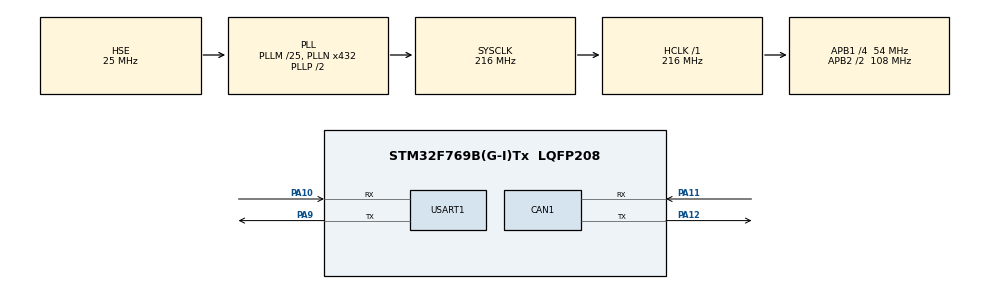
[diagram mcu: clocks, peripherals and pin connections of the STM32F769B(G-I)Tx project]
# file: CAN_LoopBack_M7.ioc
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CAN1.BS1=CAN_BS1_2TQ
CAN1.BS2=CAN_BS2_2TQ
CAN1.CalculateTimeQuantum=296.2962962962963
DSIHOST_CKN.Mode=DSIHost_Standalone
DSIHOST_CKN.Signal=DSIHOST_CKN
DSIHOST_CKP.Mode=DSIHost_Standalone
DSIHOST_CKP.Signal=DSIHOST_CKP
DSIHOST_D0N.Mode=DSIHost_Standalone
DSIHOST_D0N.Signal=DSIHOST_D0N
DSIHOST_D0P.Mode=DSIHost_Standalone
DSIHOST_D0P.Signal=DSIHOST_D0P
DSIHOST_D1N.Mode=DSIHost_Standalone
DSIHOST_D1N.Signal=DSIHOST_D1N
DSIHOST_D1P.Mode=DSIHost_Standalone
DSIHOST_D1P.Signal=DSIHOST_D1P
Mcu.Family=STM32F7
Mcu.Name=STM32F769B(G-I)Tx
Mcu.Package=LQFP208
NVIC.CAN1_RX0_IRQn=true\:0\:0\:false\:false\:true\:true\:true
NVIC.CAN1_RX1_IRQn=true\:0\:0\:false\:false\:true\:true\:true
NVIC.CAN1_SCE_IRQn=true\:0\:0\:false\:false\:true\:true\:true
NVIC.CAN1_TX_IRQn=true\:0\:0\:false\:false\:true\:true\:true
NVIC.PriorityGroup=NVIC_PRIORITYGROUP_4
PA10.Mode=Asynchronous
PA10.Signal=USART1_RX
PA11.Mode=Master
PA11.Signal=CAN1_RX
PA12.Mode=Master
PA12.Signal=CAN1_TX
PA9.Mode=Asynchronous
PA9.Signal=USART1_TX
PH0/OSC_IN.Mode=HSE-External-Oscillator
PH0/OSC_IN.Signal=RCC_OSC_IN
PH1/OSC_OUT.Mode=HSE-External-Oscillator
PH1/OSC_OUT.Signal=RCC_OSC_OUT
ProjectManager.HeapSize=0x200
ProjectManager.StackSize=0x400
ProjectManager.TargetToolchain=SW4STM32
RCC.AHBFreq_Value=216000000
RCC.APB1CLKDivider=RCC_HCLK_DIV4
RCC.APB1Freq_Value=54000000
RCC.APB1TimFreq_Value=108000000
RCC.APB2CLKDivider=RCC_HCLK_DIV2
RCC.APB2Freq_Value=108000000
RCC.APB2TimFreq_Value=216000000
RCC.CortexFreq_Value=216000000
RCC.HCLKFreq_Value=216000000
RCC.HSE_VALUE=25000000
RCC.HSI_VALUE=16000000
RCC.LSE_VALUE=32768
RCC.PLLM=25
RCC.PLLN=432
RCC.PLLSourceVirtual=RCC_PLLSOURCE_HSE
RCC.SYSCLKFreq_VALUE=216000000
RCC.SYSCLKSource=RCC_SYSCLKSOURCE_PLLCLK
RCC.USBFreq_Value=216000000
RCC.VCOOutputFreq_Value=432000000
USART1.VirtualMode-Asynchronous=VM_ASYNC
board=custom

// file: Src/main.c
/* USER CODE BEGIN Header */
/**
  ******************************************************************************
  * @file           : main.c
  * @brief          : Main program body
  ******************************************************************************
  * @attention
  *
  * <h2><center>&copy; Copyright (c) 2020 STMicroelectronics.
  * All rights reserved.</center></h2>
  *
  * This software component is licensed by ST under BSD 3-Clause license,
  * the "License"; You may not use this file except in compliance with the
  * License. You may obtain a copy of the License at:
  *                        opensource.org/licenses/BSD-3-Clause
  *
  ******************************************************************************
  */
/* USER CODE END Header */

#include "main.h"
#include <string.h>

CAN_HandleTypeDef hcan1;

DSI_HandleTypeDef hdsi;

UART_HandleTypeDef huart1;

void SystemClock_Config(void);
static void MX_GPIO_Init(void);
static void MX_CAN1_Init(void);
static void MX_USART1_UART_Init(void);
static void MX_DSIHOST_DSI_Init(void);
void CAN1Tx(void);
void CAN1Rx(void);
void CANFilterConfig(void);

int main(void)
{

  /* MCU Configuration--------------------------------------------------------*/

  /* Reset of all peripherals, Initializes the Flash interface and the Systick. */
  HAL_Init();

  /* Configure the system clock */
  SystemClock_Config();

  /* Initialize all configured peripherals */
  MX_GPIO_Init();
  MX_CAN1_Init();

  CANFilterConfig();

  // Enable Interrupts before starting CAN
  HAL_CAN_ActivateNotification(&hcan1, CAN_IT_TX_MAILBOX_EMPTY | CAN_IT_RX_FIFO0_MSG_PENDING | CAN_IT_RX_FIFO1_MSG_PENDING | CAN_IT_ERROR);

  HAL_CAN_Start(&hcan1);

  MX_USART1_UART_Init();
  MX_DSIHOST_DSI_Init();
  /* USER CODE BEGIN 2 */
  uint8_t *msg = "Greetings From the M7 in 216 Mhz glory POLLING\n";
  HAL_UART_Transmit(&huart1, msg, strlen(msg), 10);
  CAN1Tx();
  //CAN1Rx();
  /* USER CODE END 2 */

  /* Infinite loop */
  while (1)
  {
    /* USER CODE BEGIN 3 */

	//CAN1Rx();
	CAN1Tx();
	HAL_Delay(500);
  }
  /* USER CODE END 3 */
}

void CANFilterConfig() {
	CAN_FilterTypeDef filter;
	filter.FilterActivation = ENABLE;
	filter.FilterBank = 0;
	filter.FilterFIFOAssignment = CAN_RX_FIFO0;
	filter.FilterIdHigh = 0x0000;
	filter.FilterIdLow = 0x0000;

	filter.FilterMaskIdHigh = 0x0000;
	filter.FilterMaskIdLow = 0x0000;
	filter.FilterMode = CAN_FILTERMODE_IDMASK;
	filter.FilterScale = CAN_FILTERSCALE_32BIT;

	if (HAL_CAN_ConfigFilter(&hcan1, &filter)) {
		Error_Handler();
	}

}

void CAN1Tx() {
	CAN_TxHeaderTypeDef TxHeader;
	uint8_t *CANMessage = "CANBusM7";
	TxHeader.DLC = 8;
	TxHeader.StdId = 0x65D; // arbitrary standard len addr
	TxHeader.IDE = CAN_ID_STD;
	TxHeader.RTR = CAN_RTR_DATA; // we want to send a data frame not request frame

	uint32_t mailbox;

	if (HAL_CAN_AddTxMessage(&hcan1, &TxHeader, CANMessage, &mailbox) != HAL_OK) {
		Error_Handler();
	}

}

void CAN1Rx() {
	// based Rx
	CAN_RxHeaderTypeDef RxHeader;
	uint8_t recvMessage[8];
	while (!HAL_CAN_GetRxFifoFillLevel(&hcan1, CAN_RX_FIFO0));

	if (HAL_CAN_GetRxMessage(&hcan1, CAN_RX_FIFO0, &RxHeader, recvMessage) != HAL_OK) {
		Error_Handler();
	}
	//uint8_t *successMsg = "received CAN MSG!\n";
	//HAL_UART_Transmit(&huart1, successMsg, strlen(successMsg), 10);

	// Now print message contents
	HAL_UART_Transmit(&huart1, recvMessage, strlen(recvMessage), 10);

}

// CAN interrupt callbacks

void txCompleteMsg() {
	uint8_t *sucessMsg = "Msg transmit\n";
	HAL_UART_Transmit(&huart1, sucessMsg, strlen(sucessMsg), 10);
}

// TX complete interrupts
void HAL_CAN_TxMailbox0CompleteCallback(CAN_HandleTypeDef *hcan) {
	txCompleteMsg();
}

void HAL_CAN_TxMailbox1CompleteCallback(CAN_HandleTypeDef *hcan) {
	txCompleteMsg();
}
void HAL_CAN_TxMailbox2CompleteCallback(CAN_HandleTypeDef *hcan) {
	txCompleteMsg();
}

// Rx interrupts
void HAL_CAN_RxFifo0MsgPendingCallback(CAN_HandleTypeDef *hcan) {
	// based Rx
	CAN_RxHeaderTypeDef RxHeader;
	uint8_t recvMessage[8];

	if (HAL_CAN_GetRxMessage(&hcan1, CAN_RX_FIFO0, &RxHeader, recvMessage) != HAL_OK) {
		Error_Handler();
	}
	//uint8_t *successMsg = "received CAN MSG!\n";
	//HAL_UART_Transmit(&huart1, successMsg, strlen(successMsg), 10);

	// Now print message contents
	HAL_UART_Transmit(&huart1, recvMessage, strlen(recvMessage), 10);
}

void HAL_CAN_RxFifo1MsgPendingCallback(CAN_HandleTypeDef *hcan) {
	// based Rx
	CAN_RxHeaderTypeDef RxHeader;
	uint8_t recvMessage[8];

	if (HAL_CAN_GetRxMessage(&hcan1, CAN_RX_FIFO0, &RxHeader, recvMessage) != HAL_OK) {
		Error_Handler();
	}
	uint8_t *successMsg = "received CAN MSG!\n";
	HAL_UART_Transmit(&huart1, successMsg, strlen(successMsg), 10);

	// Now print message contents
	HAL_UART_Transmit(&huart1, recvMessage, strlen(recvMessage), 10);
}

// Error Callbacks
void HAL_CAN_ErrorCallback(CAN_HandleTypeDef *hcan) {
		uint8_t *successMsg = "CAN ERROR!\n";
		HAL_UART_Transmit(&huart1, successMsg, strlen(successMsg), 10);
}

void SystemClock_Config(void)
{
  RCC_OscInitTypeDef RCC_OscInitStruct = {0};
  RCC_ClkInitTypeDef RCC_ClkInitStruct = {0};
  RCC_PeriphCLKInitTypeDef PeriphClkInitStruct = {0};

  /** Configure the main internal regulator output voltage
  */
  __HAL_RCC_PWR_CLK_ENABLE();
  __HAL_PWR_VOLTAGESCALING_CONFIG(PWR_REGULATOR_VOLTAGE_SCALE1);
  /** Initializes the CPU, AHB and APB busses clocks
  */
  RCC_OscInitStruct.OscillatorType = RCC_OSCILLATORTYPE_HSE;
  RCC_OscInitStruct.HSEState = RCC_HSE_ON;
  RCC_OscInitStruct.PLL.PLLState = RCC_PLL_ON;
  RCC_OscInitStruct.PLL.PLLSource = RCC_PLLSOURCE_HSE;
  RCC_OscInitStruct.PLL.PLLM = 25;
  RCC_OscInitStruct.PLL.PLLN = 432;
  RCC_OscInitStruct.PLL.PLLP = RCC_PLLP_DIV2;
  RCC_OscInitStruct.PLL.PLLQ = 2;
  if (HAL_RCC_OscConfig(&RCC_OscInitStruct) != HAL_OK)
  {
    Error_Handler();
  }
  /** Activate the Over-Drive mode
  */
  if (HAL_PWREx_EnableOverDrive() != HAL_OK)
  {
    Error_Handler();
  }
  /** Initializes the CPU, AHB and APB busses clocks
  */
  RCC_ClkInitStruct.ClockType = RCC_CLOCKTYPE_HCLK|RCC_CLOCKTYPE_SYSCLK
                              |RCC_CLOCKTYPE_PCLK1|RCC_CLOCKTYPE_PCLK2;
  RCC_ClkInitStruct.SYSCLKSource = RCC_SYSCLKSOURCE_PLLCLK;
  RCC_ClkInitStruct.AHBCLKDivider = RCC_SYSCLK_DIV1;
  RCC_ClkInitStruct.APB1CLKDivider = RCC_HCLK_DIV4;
  RCC_ClkInitStruct.APB2CLKDivider = RCC_HCLK_DIV2;

  if (HAL_RCC_ClockConfig(&RCC_ClkInitStruct, FLASH_LATENCY_7) != HAL_OK)
  {
    Error_Handler();
  }
  PeriphClkInitStruct.PeriphClockSelection = RCC_PERIPHCLK_USART1;
  PeriphClkInitStruct.Usart1ClockSelection = RCC_USART1CLKSOURCE_PCLK2;
  if (HAL_RCCEx_PeriphCLKConfig(&PeriphClkInitStruct) != HAL_OK)
  {
    Error_Handler();
  }
}

static void MX_CAN1_Init(void)
{

  hcan1.Instance = CAN1;
  hcan1.Init.Prescaler = 12;
  hcan1.Init.Mode = CAN_MODE_NORMAL;
  hcan1.Init.SyncJumpWidth = CAN_SJW_1TQ;
  hcan1.Init.TimeSeg1 = CAN_BS1_15TQ;
  hcan1.Init.TimeSeg2 = CAN_BS2_2TQ;
  hcan1.Init.TimeTriggeredMode = DISABLE;
  hcan1.Init.AutoBusOff = DISABLE;
  hcan1.Init.AutoWakeUp = DISABLE;
  hcan1.Init.AutoRetransmission = ENABLE;
  hcan1.Init.ReceiveFifoLocked = DISABLE;
  hcan1.Init.TransmitFifoPriority = DISABLE;
  if (HAL_CAN_Init(&hcan1) != HAL_OK)
  {
    Error_Handler();
  }

}

static void MX_DSIHOST_DSI_Init(void)
{

  DSI_PLLInitTypeDef PLLInit = {0};
  DSI_HOST_TimeoutTypeDef HostTimeouts = {0};
  DSI_PHY_TimerTypeDef PhyTimings = {0};
  DSI_LPCmdTypeDef LPCmd = {0};

  hdsi.Instance = DSI;
  hdsi.Init.AutomaticClockLaneControl = DSI_AUTO_CLK_LANE_CTRL_DISABLE;
  hdsi.Init.TXEscapeCkdiv = 4;
  hdsi.Init.NumberOfLanes = DSI_ONE_DATA_LANE;
  PLLInit.PLLNDIV = 20;
  PLLInit.PLLIDF = DSI_PLL_IN_DIV1;
  PLLInit.PLLODF = DSI_PLL_OUT_DIV1;
  if (HAL_DSI_Init(&hdsi, &PLLInit) != HAL_OK)
  {
    Error_Handler();
  }
  HostTimeouts.TimeoutCkdiv = 1;
  HostTimeouts.HighSpeedTransmissionTimeout = 0;
  HostTimeouts.LowPowerReceptionTimeout = 0;
  HostTimeouts.HighSpeedReadTimeout = 0;
  HostTimeouts.LowPowerReadTimeout = 0;
  HostTimeouts.HighSpeedWriteTimeout = 0;
  HostTimeouts.HighSpeedWritePrespMode = DSI_HS_PM_DISABLE;
  HostTimeouts.LowPowerWriteTimeout = 0;
  HostTimeouts.BTATimeout = 0;
  if (HAL_DSI_ConfigHostTimeouts(&hdsi, &HostTimeouts) != HAL_OK)
  {
    Error_Handler();
  }
  PhyTimings.ClockLaneHS2LPTime = 28;
  PhyTimings.ClockLaneLP2HSTime = 33;
  PhyTimings.DataLaneHS2LPTime = 15;
  PhyTimings.DataLaneLP2HSTime = 25;
  PhyTimings.DataLaneMaxReadTime = 0;
  PhyTimings.StopWaitTime = 0;

  if (HAL_DSI_ConfigPhyTimer(&hdsi, &PhyTimings) != HAL_OK)
  {
    Error_Handler();
  }
  if (HAL_DSI_ConfigFlowControl(&hdsi, DSI_FLOW_CONTROL_BTA) != HAL_OK)
  {
    Error_Handler();
  }
  if (HAL_DSI_SetLowPowerRXFilter(&hdsi, 10000) != HAL_OK)
  {
    Error_Handler();
  }
  if (HAL_DSI_ConfigErrorMonitor(&hdsi, HAL_DSI_ERROR_NONE) != HAL_OK)
  {
    Error_Handler();
  }
  LPCmd.LPGenShortWriteNoP = DSI_LP_GSW0P_DISABLE;
  LPCmd.LPGenShortWriteOneP = DSI_LP_GSW1P_DISABLE;
  LPCmd.LPGenShortWriteTwoP = DSI_LP_GSW2P_DISABLE;
  LPCmd.LPGenShortReadNoP = DSI_LP_GSR0P_DISABLE;
  LPCmd.LPGenShortReadOneP = DSI_LP_GSR1P_DISABLE;
  LPCmd.LPGenShortReadTwoP = DSI_LP_GSR2P_DISABLE;
  LPCmd.LPGenLongWrite = DSI_LP_GLW_DISABLE;
  LPCmd.LPDcsShortWriteNoP = DSI_LP_DSW0P_DISABLE;
  LPCmd.LPDcsShortWriteOneP = DSI_LP_DSW1P_DISABLE;
  LPCmd.LPDcsShortReadNoP = DSI_LP_DSR0P_DISABLE;
  LPCmd.LPDcsLongWrite = DSI_LP_DLW_DISABLE;
  LPCmd.LPMaxReadPacket = DSI_LP_MRDP_DISABLE;
  LPCmd.AcknowledgeRequest = DSI_ACKNOWLEDGE_DISABLE;
  if (HAL_DSI_ConfigCommand(&hdsi, &LPCmd) != HAL_OK)
  {
    Error_Handler();
  }

}

static void MX_USART1_UART_Init(void)
{

  huart1.Instance = USART1;
  huart1.Init.BaudRate = 115200;
  huart1.Init.WordLength = UART_WORDLENGTH_8B;
  huart1.Init.StopBits = UART_STOPBITS_1;
  huart1.Init.Parity = UART_PARITY_NONE;
  huart1.Init.Mode = UART_MODE_TX_RX;
  huart1.Init.HwFlowCtl = UART_HWCONTROL_NONE;
  huart1.Init.OverSampling = UART_OVERSAMPLING_16;
  huart1.Init.OneBitSampling = UART_ONE_BIT_SAMPLE_DISABLE;
  huart1.AdvancedInit.AdvFeatureInit = UART_ADVFEATURE_NO_INIT;
  if (HAL_UART_Init(&huart1) != HAL_OK)
  {
    Error_Handler();
  }

}

static void MX_GPIO_Init(void)
{

  /* GPIO Ports Clock Enable */
  __HAL_RCC_GPIOH_CLK_ENABLE();
  __HAL_RCC_GPIOA_CLK_ENABLE();

}

void Error_Handler(void)
{
  /* USER CODE BEGIN Error_Handler_Debug */
  /* User can add his own implementation to report the HAL error return state */
	uint8_t *successMsg = "ERROR! HANDLER\n";
	HAL_UART_Transmit(&huart1, successMsg, strlen(successMsg), 10);
	while(1);
  /* USER CODE END Error_Handler_Debug */
}

/************************ (C) COPYRIGHT STMicroelectronics *****END OF FILE****/
